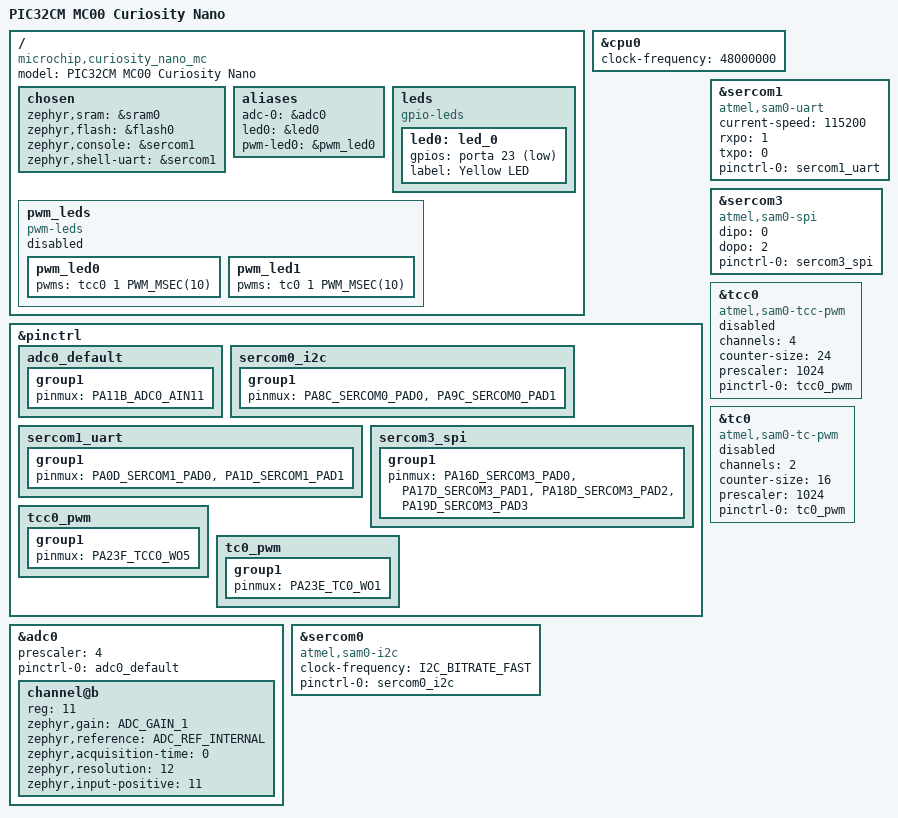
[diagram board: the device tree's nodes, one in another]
/*
 * Copyright (c) 2025 GP Orcullo
 *
 * SPDX-License-Identifier: Apache-2.0
 */

/dts-v1/;

#include <microchip/pic32cm1216mcxx.dtsi>
#include <microchip/pic32cmxxmc00032.dtsi>
#include <zephyr/dt-bindings/adc/adc.h>
#include <zephyr/dt-bindings/gpio/gpio.h>
#include <zephyr/dt-bindings/i2c/i2c.h>
#include <zephyr/dt-bindings/pinctrl/atmel_sam_pinctrl.h>
#include <zephyr/dt-bindings/pwm/pwm.h>

#define PA0D_SERCOM1_PAD0 SAM_PINMUX(a, 0, d, periph)
#define PA1D_SERCOM1_PAD1 SAM_PINMUX(a, 1, d, periph)
#define PA8C_SERCOM0_PAD0 SAM_PINMUX(a, 8, c, periph)
#define PA9C_SERCOM0_PAD1 SAM_PINMUX(a, 9, c, periph)
#define PA16D_SERCOM3_PAD0 SAM_PINMUX(a, 16, d, periph)
#define PA17D_SERCOM3_PAD1 SAM_PINMUX(a, 17, d, periph)
#define PA18D_SERCOM3_PAD2 SAM_PINMUX(a, 18, d, periph)
#define PA19D_SERCOM3_PAD3 SAM_PINMUX(a, 19, d, periph)

#define PA23F_TCC0_WO5 SAM_PINMUX(a, 23, f, periph)
#define PA23E_TC0_WO1 SAM_PINMUX(a, 23, e, periph)

#define PA11B_ADC0_AIN11 SAM_PINMUX(a, 11, b, periph)

/ {
	model = "PIC32CM MC00 Curiosity Nano";
	compatible = "microchip,curiosity_nano_mc";

	chosen {
		zephyr,sram = &sram0;
		zephyr,flash = &flash0;
		zephyr,console = &sercom1;
		zephyr,shell-uart = &sercom1;
	};

	aliases {
		adc-0 = &adc0;
		led0 = &led0;
		pwm-led0 = &pwm_led0;
	};

	leds {
		status = "okay";
		compatible = "gpio-leds";
		led0: led_0 {
			gpios = <&porta 23 GPIO_ACTIVE_LOW>;
			label = "Yellow LED";
		};
	};

	pwm_leds {
		status = "disabled";
		compatible = "pwm-leds";

		pwm_led0: pwm_led0 {
			pwms = <&tcc0 1 PWM_MSEC(10)>;
		};

		pwm_led1: pwm_led1 {
			pwms = <&tc0 1 PWM_MSEC(10)>;
		};
	};
};

&cpu0 {
	clock-frequency = <48000000>;
};

&pinctrl {
	adc0_default: adc0_default {
		group1 {
			pinmux = <PA11B_ADC0_AIN11>;
		};
	};

	sercom0_i2c: sercom0_i2c {
		group1 {
			pinmux = <PA8C_SERCOM0_PAD0>,
				 <PA9C_SERCOM0_PAD1>;
		};
	};

	sercom1_uart: sercom1_uart {
		group1 {
			pinmux = <PA0D_SERCOM1_PAD0>,
				 <PA1D_SERCOM1_PAD1>;
		};
	};

	sercom3_spi: sercom3_spi {
		group1 {
			pinmux = <PA16D_SERCOM3_PAD0>,
				 <PA17D_SERCOM3_PAD1>,
				 <PA18D_SERCOM3_PAD2>,
				 <PA19D_SERCOM3_PAD3>;
		};
	};

	tcc0_pwm: tcc0_pwm {
		group1 {
			pinmux = <PA23F_TCC0_WO5>;
		};
	};

	tc0_pwm: tc0_pwm {
		group1 {
			pinmux = <PA23E_TC0_WO1>;
		};
	};
};

&adc0 {
	status = "okay";
	prescaler = <4>;
	pinctrl-0 = <&adc0_default>;
	pinctrl-names = "default";
	#address-cells = <1>;
	#size-cells = <0>;
	channel@b {
		reg = <11>;
		zephyr,gain = "ADC_GAIN_1";
		zephyr,reference = "ADC_REF_INTERNAL";
		zephyr,acquisition-time = <0>;
		zephyr,resolution = <12>;
		zephyr,input-positive = <11>;
	};
};

&sercom0 {
	status = "okay";
	compatible = "atmel,sam0-i2c";
	clock-frequency = <I2C_BITRATE_FAST>;
	#address-cells = <1>;
	#size-cells = <0>;

	pinctrl-0 = <&sercom0_i2c>;
	pinctrl-names = "default";
};

&sercom1 {
	status = "okay";
	compatible = "atmel,sam0-uart";
	current-speed = <115200>;
	rxpo = <1>;
	txpo = <0>;

	pinctrl-0 = <&sercom1_uart>;
	pinctrl-names = "default";
};

&sercom3 {
	status = "okay";
	compatible = "atmel,sam0-spi";
	dipo = <0>;
	dopo = <2>;
	#address-cells = <1>;
	#size-cells = <0>;

	pinctrl-0 = <&sercom3_spi>;
	pinctrl-names = "default";
};

&tcc0 {
	status = "disabled";
	compatible = "atmel,sam0-tcc-pwm";
	channels = <4>;
	counter-size = <24>;
	prescaler = <1024>;
	#pwm-cells = <2>;

	pinctrl-0 = <&tcc0_pwm>;
	pinctrl-names = "default";
};

&tc0 {
	status = "disabled";
	compatible = "atmel,sam0-tc-pwm";
	channels = <2>;
	counter-size = <16>;
	prescaler = <1024>;
	#pwm-cells = <2>;

	pinctrl-0 = <&tc0_pwm>;
	pinctrl-names = "default";
};
